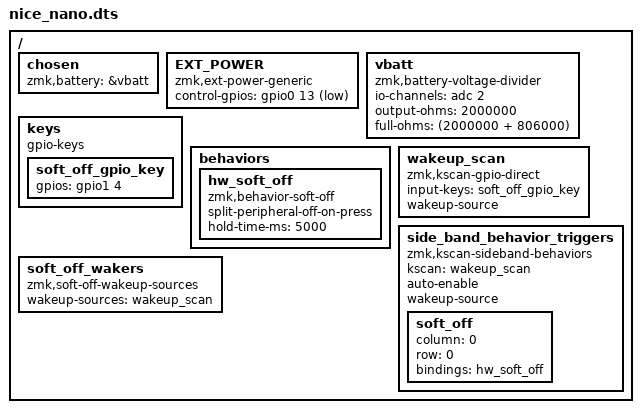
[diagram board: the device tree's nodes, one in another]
/*
 * Copyright (c) 2021 The ZMK Contributors
 *
 * SPDX-License-Identifier: MIT
 */

/dts-v1/;
#include "nice_nano.dtsi"

/ {
    chosen {
        zmk,battery = &vbatt;
    };

    // Node name must match original "EXT_POWER" label to preserve user settings.
    EXT_POWER {
        compatible = "zmk,ext-power-generic";
        control-gpios = <&gpio0 13 GPIO_ACTIVE_LOW>;
    };

    vbatt: vbatt {
        compatible = "zmk,battery-voltage-divider";
        io-channels = <&adc 2>;
        output-ohms = <2000000>;
        full-ohms = <(2000000 + 806000)>;
    };

    keys {
        compatible = "gpio-keys";
        soft_off_gpio_key: soft_off_gpio_key {
            gpios = <&gpio1 4 (GPIO_ACTIVE_HIGH | GPIO_PULL_DOWN)>;
        };
    };

    behaviors {
        hw_soft_off: hw_soft_off {
            compatible = "zmk,behavior-soft-off";
            #binding-cells = <0>;
            split-peripheral-off-on-press;
            hold-time-ms = <5000>;
        };
    };

    wakeup_scan: wakeup_scan {
        compatible = "zmk,kscan-gpio-direct";
        input-keys = <&soft_off_gpio_key>;
        wakeup-source;
    };

    side_band_behavior_triggers: side_band_behavior_triggers {
        compatible = "zmk,kscan-sideband-behaviors";
        kscan = <&wakeup_scan>;
        auto-enable;
        wakeup-source;

        soft_off {
            column = <0>;
            row = <0>;
            bindings = <&hw_soft_off>;
        };
    };

    soft_off_wakers {
        compatible = "zmk,soft-off-wakeup-sources";
        wakeup-sources = <&wakeup_scan>;
    };
};
